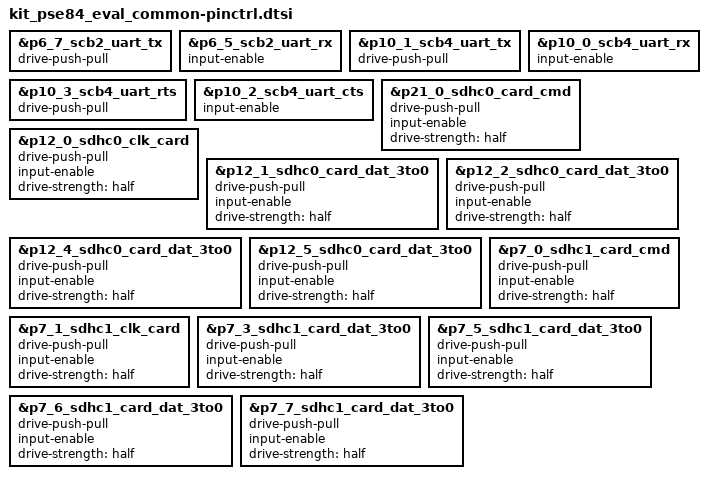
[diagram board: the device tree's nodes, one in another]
/*
 * Copyright (c) 2025 Infineon Technologies AG,
 * or an affiliate of Infineon Technologies AG.
 *
 * SPDX-License-Identifier: Apache-2.0
 */

/* Configure pin control bias mode for uart2 pins */
&p6_7_scb2_uart_tx {
	drive-push-pull;
};

&p6_5_scb2_uart_rx {
	input-enable;
};

&p10_1_scb4_uart_tx {
	drive-push-pull;
};

&p10_0_scb4_uart_rx {
	input-enable;
};

&p10_3_scb4_uart_rts {
	drive-push-pull;
};

&p10_2_scb4_uart_cts {
	input-enable;
};

&p21_0_sdhc0_card_cmd {
	drive-push-pull;
	input-enable;
	drive-strength = "half";
};

&p12_0_sdhc0_clk_card {
	drive-push-pull;
	input-enable;
	drive-strength = "half";
};

&p12_1_sdhc0_card_dat_3to0 {
	drive-push-pull;
	input-enable;
	drive-strength = "half";
};

&p12_2_sdhc0_card_dat_3to0 {
	drive-push-pull;
	input-enable;
	drive-strength = "half";
};

&p12_4_sdhc0_card_dat_3to0 {
	drive-push-pull;
	input-enable;
	drive-strength = "half";
};

&p12_5_sdhc0_card_dat_3to0 {
	drive-push-pull;
	input-enable;
	drive-strength = "half";
};

&p7_0_sdhc1_card_cmd {
	drive-push-pull;
	input-enable;
	drive-strength = "half";
};

&p7_1_sdhc1_clk_card {
	drive-push-pull;
	input-enable;
	drive-strength = "half";
};

&p7_3_sdhc1_card_dat_3to0 {
	drive-push-pull;
	input-enable;
	drive-strength = "half";
};

&p7_5_sdhc1_card_dat_3to0 {
	drive-push-pull;
	input-enable;
	drive-strength = "half";
};

&p7_6_sdhc1_card_dat_3to0 {
	drive-push-pull;
	input-enable;
	drive-strength = "half";
};

&p7_7_sdhc1_card_dat_3to0 {
	drive-push-pull;
	input-enable;
	drive-strength = "half";
};
